# STM32L412TBY6P register map
File version: 1.0
Registers are 32-bit, access not given, reset 0x0 unless marked. A register's access mark holds for its fields unless they carry their own. Offsets are from the block's base; [hi:lo] are bit positions; {n}, {i} and the like mark numbered series.

## CRS
Base 0x40006000
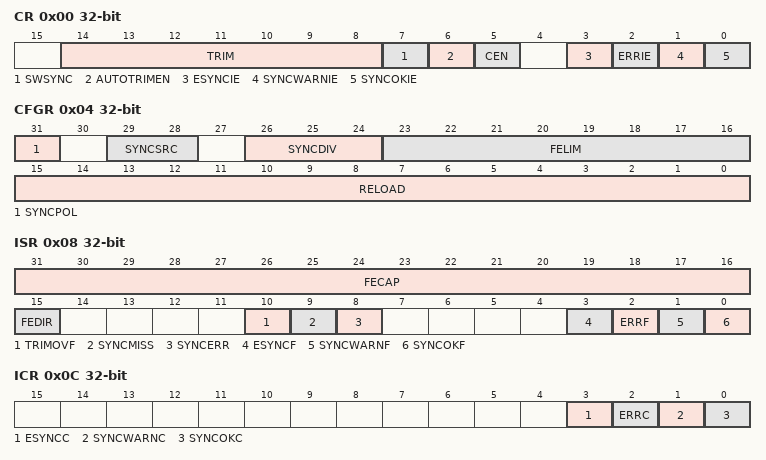
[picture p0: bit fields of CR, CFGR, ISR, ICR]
0x00 CR
  [14:8] TRIM, [7] SWSYNC, [6] AUTOTRIMEN, [5] CEN, [3] ESYNCIE, [2] ERRIE, [1] SYNCWARNIE, [0] SYNCOKIE
0x04 CFGR
  [31] SYNCPOL, [29:28] SYNCSRC, [26:24] SYNCDIV, [23:16] FELIM, [15:0] RELOAD
0x08 ISR
  [31:16] FECAP, [15] FEDIR, [10] TRIMOVF, [9] SYNCMISS, [8] SYNCERR, [3] ESYNCF, [2] ERRF, [1] SYNCWARNF, [0] SYNCOKF
0x0C ICR
  [3] ESYNCC, [2] ERRC, [1] SYNCWARNC, [0] SYNCOKC

## USB
Base 0x40006800
{0x0+4i} EP{i}R 16-bit (i=0..7)
0x40 CNTR 16-bit
0x44 ISTR 16-bit
0x48 FNR 16-bit
0x4C DADDR 16-bit
0x50 BTABLE 16-bit
0x54 LPMCSR 16-bit
0x58 BCDR 16-bit

## PWR
Base 0x40007000
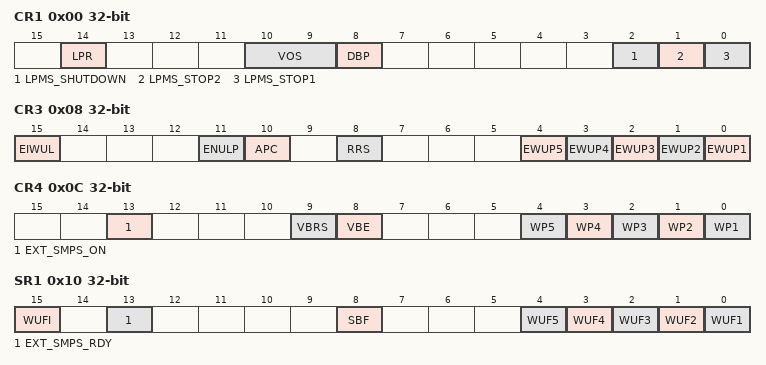
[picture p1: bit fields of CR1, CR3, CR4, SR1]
0x00 CR1
  [14] LPR, [10:9] VOS, [8] DBP, [2] LPMS_SHUTDOWN, [1] LPMS_STOP2, [0] LPMS_STOP1
0x04 CR2
  [10] USV, [7] PVME4, [6] PVME3, [4] PVME1, [3] PLS_LEV4, [3:2] PLS_LEV6, [3:1] PLS_LEV7, [0] PVDE
0x08 CR3
  [15] EIWUL, [11] ENULP, [10] APC, [8] RRS, [n-1] EWUP{n} (n=1..5)
0x0C CR4
  [13] EXT_SMPS_ON, [9] VBRS, [8] VBE, [n-1] WP{n} (n=1..5)
0x10 SR1
  [15] WUFI, [13] EXT_SMPS_RDY, [8] SBF, [n-1] WUF{n} (n=1..5)
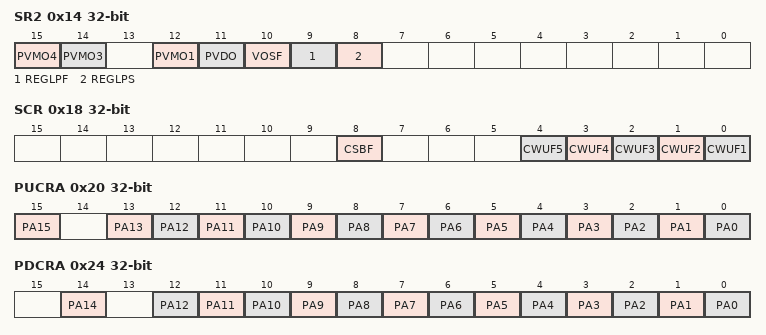
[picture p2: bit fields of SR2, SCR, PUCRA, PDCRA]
0x14 SR2
  [15] PVMO4, [14] PVMO3, [12] PVMO1, [11] PVDO, [10] VOSF, [9] REGLPF, [8] REGLPS
0x18 SCR
  [8] CSBF, [n-1] CWUF{n} (n=1..5)
0x20 PUCRA
  [15] PA15, [n] PA{n} (n=0..13)
0x24 PDCRA
  [14] PA14, [n] PA{n} (n=0..12)
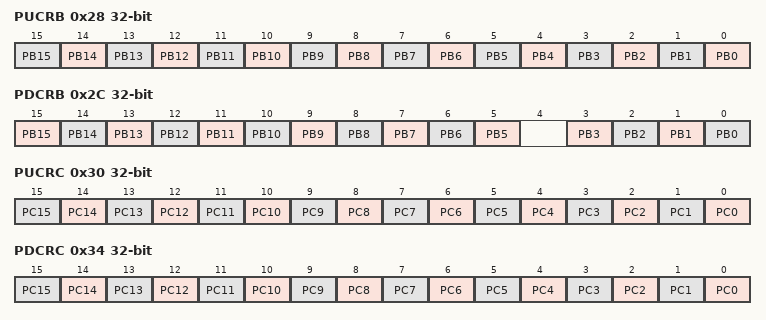
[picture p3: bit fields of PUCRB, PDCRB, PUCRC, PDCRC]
0x28 PUCRB
  [n] PB{n} (n=0..15)
0x2C PDCRB
  [n] PB{n} (n=5..15), [n] PB{n} (n=0..3)
0x30 PUCRC
  [n] PC{n} (n=0..15)
0x34 PDCRC
  [n] PC{n} (n=0..15)
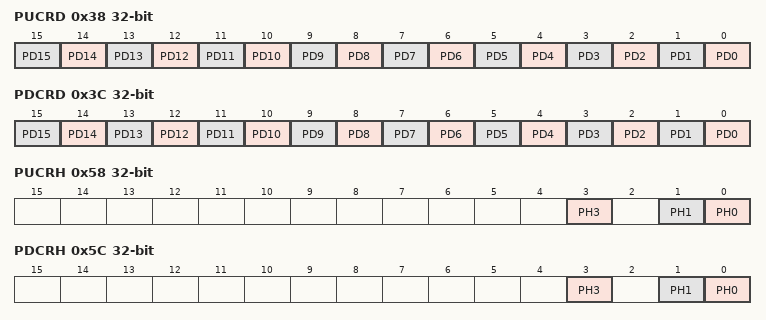
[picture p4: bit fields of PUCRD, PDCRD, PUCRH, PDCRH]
0x38 PUCRD
  [n] PD{n} (n=0..15)
0x3C PDCRD
  [n] PD{n} (n=0..15)
0x40 PUCRE
0x44 PDCRE
0x58 PUCRH
  [3] PH3, [1] PH1, [0] PH0
0x5C PDCRH
  [3] PH3, [1] PH1, [0] PH0

## OPAMP
Base 0x40007800
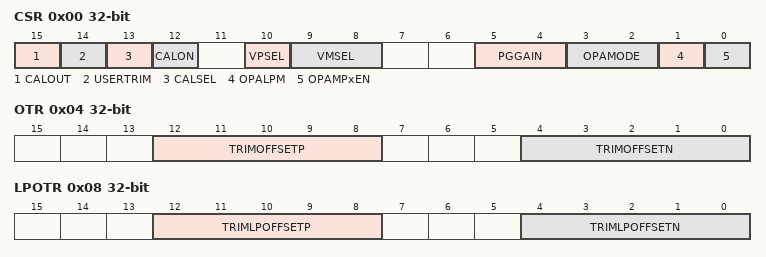
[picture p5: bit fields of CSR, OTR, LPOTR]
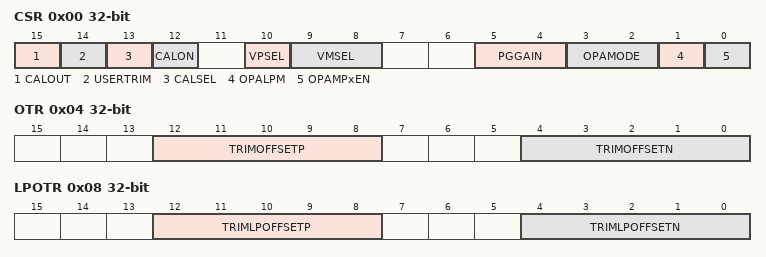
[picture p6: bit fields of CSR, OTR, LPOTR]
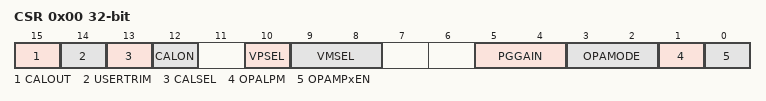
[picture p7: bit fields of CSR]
0x00 CSR
  [15] CALOUT, [14] USERTRIM, [13] CALSEL, [12] CALON, [10] VPSEL, [9:8] VMSEL, [5:4] PGGAIN, [3:2] OPAMODE, [1] OPALPM, [0] OPAMPxEN
0x04 OTR
  [12:8] TRIMOFFSETP, [4:0] TRIMOFFSETN
0x08 LPOTR
  [12:8] TRIMLPOFFSETP, [4:0] TRIMLPOFFSETN

## OPAMP1
Base 0x40007800
0x00 CSR
  [15] CALOUT, [14] USERTRIM, [13] CALSEL, [12] CALON, [10] VPSEL, [9:8] VMSEL, [5:4] PGGAIN, [3:2] OPAMODE, [1] OPALPM, [0] OPAMPxEN
0x04 OTR
  [12:8] TRIMOFFSETP, [4:0] TRIMOFFSETN
0x08 LPOTR
  [12:8] TRIMLPOFFSETP, [4:0] TRIMLPOFFSETN

## OPAMP1_COMMON
Base 0x40007800
0x00 CSR
  [15] CALOUT, [14] USERTRIM, [13] CALSEL, [12] CALON, [10] VPSEL, [9:8] VMSEL, [5:4] PGGAIN, [3:2] OPAMODE, [1] OPALPM, [0] OPAMPxEN

## LPTIM1
Base 0x40007C00
Same registers: LPTIM2 0x40009400
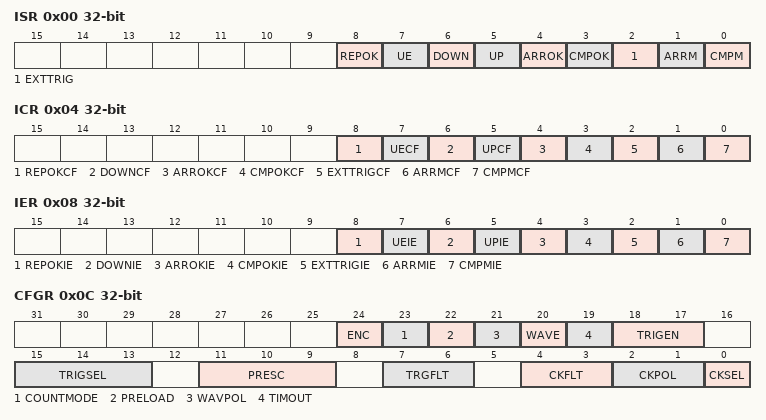
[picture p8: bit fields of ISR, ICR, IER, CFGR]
0x00 ISR
  [8] REPOK, [7] UE, [6] DOWN, [5] UP, [4] ARROK, [3] CMPOK, [2] EXTTRIG, [1] ARRM, [0] CMPM
0x04 ICR
  [8] REPOKCF, [7] UECF, [6] DOWNCF, [5] UPCF, [4] ARROKCF, [3] CMPOKCF, [2] EXTTRIGCF, [1] ARRMCF, [0] CMPMCF
0x08 IER
  [8] REPOKIE, [7] UEIE, [6] DOWNIE, [5] UPIE, [4] ARROKIE, [3] CMPOKIE, [2] EXTTRIGIE, [1] ARRMIE, [0] CMPMIE
0x0C CFGR
  [24] ENC, [23] COUNTMODE, [22] PRELOAD, [21] WAVPOL, [20] WAVE, [19] TIMOUT, [18:17] TRIGEN, [15:13] TRIGSEL, [11:9] PRESC, [7:6] TRGFLT, [4:3] CKFLT, [2:1] CKPOL, [0] CKSEL
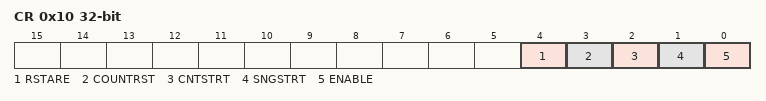
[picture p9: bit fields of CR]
0x10 CR
  [4] RSTARE, [3] COUNTRST, [2] CNTSTRT, [1] SNGSTRT, [0] ENABLE
0x14 CMP
  [15:0] CMP
0x18 ARR
  [15:0] ARR
0x1C CNT
  [15:0] CNT
0x20 OR
  [1:0] OR
0x28 RCR
  [7:0] REP

## SYSCFG
Base 0x40010000
0x00 MEMRMP
  [2:0] MEM_MODE
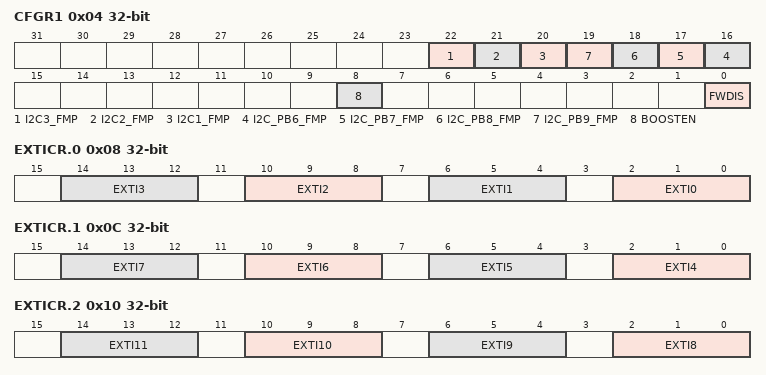
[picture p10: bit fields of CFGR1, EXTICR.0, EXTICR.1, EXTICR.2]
0x04 CFGR1
  [22] I2C3_FMP, [21] I2C2_FMP, [20] I2C1_FMP, [n+10] I2C_PB{n}_FMP (n=6..9), [8] BOOSTEN, [0] FWDIS
0x08 EXTICR.0
  [4n+2:4n] EXTI{n} (n=0..3)
0x0C EXTICR.1
  [4n-14:4n-16] EXTI{n} (n=4..7)
0x10 EXTICR.2
  [4n-30:4n-32] EXTI{n} (n=8..11)
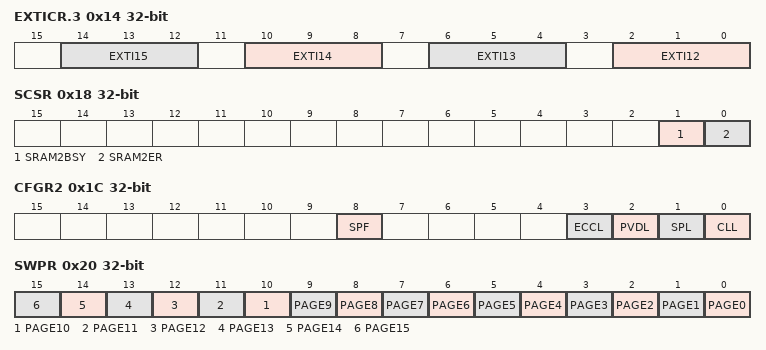
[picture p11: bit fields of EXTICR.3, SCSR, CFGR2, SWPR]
0x14 EXTICR.3
  [4n-46:4n-48] EXTI{n} (n=12..15)
0x18 SCSR
  [1] SRAM2BSY, [0] SRAM2ER
0x1C CFGR2
  [8] SPF, [3] ECCL, [2] PVDL, [1] SPL, [0] CLL
0x20 SWPR
  [n] PAGE{n} (n=0..15)
0x24 SKR
  [7:0] KEY
